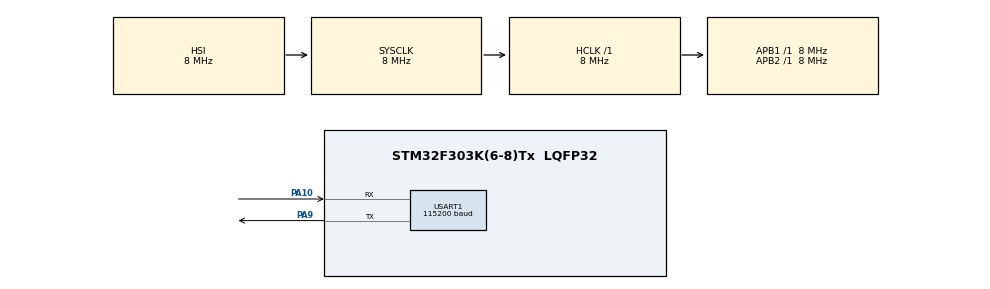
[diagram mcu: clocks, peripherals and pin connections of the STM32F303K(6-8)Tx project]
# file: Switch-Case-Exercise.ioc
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Mcu.Family=STM32F3
Mcu.Name=STM32F303K(6-8)Tx
Mcu.Package=LQFP32
NVIC.PriorityGroup=NVIC_PRIORITYGROUP_4
PA10.Mode=Asynchronous
PA10.Signal=USART1_RX
PA9.Mode=Asynchronous
PA9.Signal=USART1_TX
ProjectManager.HeapSize=0x200
ProjectManager.StackSize=0x400
ProjectManager.TargetToolchain=STM32CubeIDE
RCC.AHBFreq_Value=8000000
RCC.APB1Freq_Value=8000000
RCC.APB2Freq_Value=8000000
RCC.CortexFreq_Value=8000000
RCC.HSE_VALUE=8000000
RCC.HSI_VALUE=8000000
RCC.SYSCLKFreq_VALUE=8000000
USART1.BaudRate=115200
USART1.VirtualMode-Asynchronous=VM_ASYNC
board=custom

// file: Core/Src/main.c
/* USER CODE BEGIN Header */
/**
  ******************************************************************************
  * @file           : main.c
  * @brief          : Main program body
  ******************************************************************************
  * @attention
  *
  * Copyright (c) 2022 STMicroelectronics.
  * All rights reserved.
  *
  * This software is licensed under terms that can be found in the LICENSE file
  * in the root directory of this software component.
  * If no LICENSE file comes with this software, it is provided AS-IS.
  *
  ******************************************************************************
  */
/* USER CODE END Header */
#include "main.h"
#include <console.h>
#include <stdio.h>

 UART_HandleTypeDef huart1;

void SystemClock_Config(void);
static void MX_GPIO_Init(void);
static void MX_USART1_UART_Init(void);

int main(void)
{

  /* MCU Configuration--------------------------------------------------------*/

  /* Reset of all peripherals, Initializes the Flash interface and the Systick. */
  HAL_Init();

  /* Configure the system clock */
  SystemClock_Config();

  /* Initialize all configured peripherals */
  MX_GPIO_Init();
  MX_USART1_UART_Init();
  /* USER CODE BEGIN 2 */

  char code;

//  Circle
  int radius;
//  Triangle
  int base, height;
//  Rectangle
  int width,length;
//  Square
  int side;
//  Trapezoid
  int Abase,Bbase,Theight;

//  Area
  float Acircle,Atriangle,Arectangle,Asquare,Atrapezoid;

  fflush(stdout);
  setvbuf( stdin, NULL, _IONBF, 0 );

//  Instructions
  printf("Circle --> c \r\n");
  printf("Triangle --> t \r\n");
  printf("Rectangle --> r \r\n");
  printf("Square --> s \r\n");
  printf("Trapezoid --> z \r\n");
  printf("Enter the code here: \r\n");
  scanf("%c",&code);

  printf("\r\n");
  switch(code)
  {
//  Circle
    case 'c' :
    {
       printf("Circle Area Calculation \r\n");
       printf("Enter the radius value: \r\n");
       fflush(stdout);
       setvbuf( stdin, NULL, _IONBF, 0 );
       scanf("%d",&radius);
       if(radius < 0)
       {
    	  printf("error \r\n");
		  break;
       }
       Acircle = 3.14 *  (radius * radius);
       printf("Area = %f \r\n",Acircle);
       break;
   }

//  Triangle
    case 't' :
        {
           printf("Triangle Area Calculation \r\n");
           printf("Enter the base value: \r\n");
           scanf("%d",&base);
           printf("Enter the height value: \r\n");
           scanf("%d",&height);
           if(radius < 0)
           {
        	  printf("error \r\n");
    		  break;
           }
    	   Atriangle = (height * base) / 2;
    	   printf("Area = %f \r\n",Atriangle);
    	   break;
        }

//  Rectangle
    case 'r' :
        {
           printf("Rectangle Area Calculation \r\n");
           printf("Enter the width value: \r\n");
           scanf("%d",&width);
           printf("Enter the length value: \r\n");
           scanf("%d",&length);
           if(radius < 0)
           {
        	  printf("error \r\n");
    		  break;
           }
           Arectangle = width *length;
           printf("Area = %f \r\n",Arectangle);
           break;
        }

//  Square
    case 's' :
            {
               printf("Square Area Calculation \r\n");
               printf("Enter the side value: \r\n");
               scanf("%d",&side);
               if(radius < 0)
               {
            	  printf("error \r\n");
        		  break;
               }
               Asquare = side *side;
               printf("Area = %f \r\n",Asquare);
               break;
            }

//  Trapezoid
    case 'z' :
            {
               printf("Trapezoid Area Calculation \r\n");
               printf("Enter the Abase value: \r\n");
               scanf("%d",&Abase);
               printf("Enter the Bbase value: \r\n");
               scanf("%d",&Bbase);
               printf("Enter the height value: \r\n");
               scanf("%d",&Theight);
               if(radius < 0)
               {
            	  printf("error \r\n");
        		  break;
               }
               Atrapezoid = ((Abase + Bbase) / 2)* Theight ;
               printf("Area = %f \r\n",Atrapezoid);
               break;
            }

    default:
    	printf("This character does not exist \r\n");
  }

  /* USER CODE END 2 */

  /* Infinite loop */
  while (1)
  {

  }
}

void SystemClock_Config(void)
{
  RCC_OscInitTypeDef RCC_OscInitStruct = {0};
  RCC_ClkInitTypeDef RCC_ClkInitStruct = {0};
  RCC_PeriphCLKInitTypeDef PeriphClkInit = {0};

  /** Initializes the RCC Oscillators according to the specified parameters
  * in the RCC_OscInitTypeDef structure.
  */
  RCC_OscInitStruct.OscillatorType = RCC_OSCILLATORTYPE_HSI;
  RCC_OscInitStruct.HSIState = RCC_HSI_ON;
  RCC_OscInitStruct.HSICalibrationValue = RCC_HSICALIBRATION_DEFAULT;
  RCC_OscInitStruct.PLL.PLLState = RCC_PLL_NONE;
  if (HAL_RCC_OscConfig(&RCC_OscInitStruct) != HAL_OK)
  {
    Error_Handler();
  }

  /** Initializes the CPU, AHB and APB buses clocks
  */
  RCC_ClkInitStruct.ClockType = RCC_CLOCKTYPE_HCLK|RCC_CLOCKTYPE_SYSCLK
                              |RCC_CLOCKTYPE_PCLK1|RCC_CLOCKTYPE_PCLK2;
  RCC_ClkInitStruct.SYSCLKSource = RCC_SYSCLKSOURCE_HSI;
  RCC_ClkInitStruct.AHBCLKDivider = RCC_SYSCLK_DIV1;
  RCC_ClkInitStruct.APB1CLKDivider = RCC_HCLK_DIV1;
  RCC_ClkInitStruct.APB2CLKDivider = RCC_HCLK_DIV1;

  if (HAL_RCC_ClockConfig(&RCC_ClkInitStruct, FLASH_LATENCY_0) != HAL_OK)
  {
    Error_Handler();
  }
  PeriphClkInit.PeriphClockSelection = RCC_PERIPHCLK_USART1;
  PeriphClkInit.Usart1ClockSelection = RCC_USART1CLKSOURCE_PCLK1;
  if (HAL_RCCEx_PeriphCLKConfig(&PeriphClkInit) != HAL_OK)
  {
    Error_Handler();
  }
}

static void MX_USART1_UART_Init(void)
{

  huart1.Instance = USART1;
  huart1.Init.BaudRate = 115200;
  huart1.Init.WordLength = UART_WORDLENGTH_8B;
  huart1.Init.StopBits = UART_STOPBITS_1;
  huart1.Init.Parity = UART_PARITY_NONE;
  huart1.Init.Mode = UART_MODE_TX_RX;
  huart1.Init.HwFlowCtl = UART_HWCONTROL_NONE;
  huart1.Init.OverSampling = UART_OVERSAMPLING_16;
  huart1.Init.OneBitSampling = UART_ONE_BIT_SAMPLE_DISABLE;
  huart1.AdvancedInit.AdvFeatureInit = UART_ADVFEATURE_NO_INIT;
  if (HAL_UART_Init(&huart1) != HAL_OK)
  {
    Error_Handler();
  }

}

static void MX_GPIO_Init(void)
{

  /* GPIO Ports Clock Enable */
  __HAL_RCC_GPIOA_CLK_ENABLE();

}

void Error_Handler(void)
{
  __disable_irq();
  while (1)
  {
  }
}
